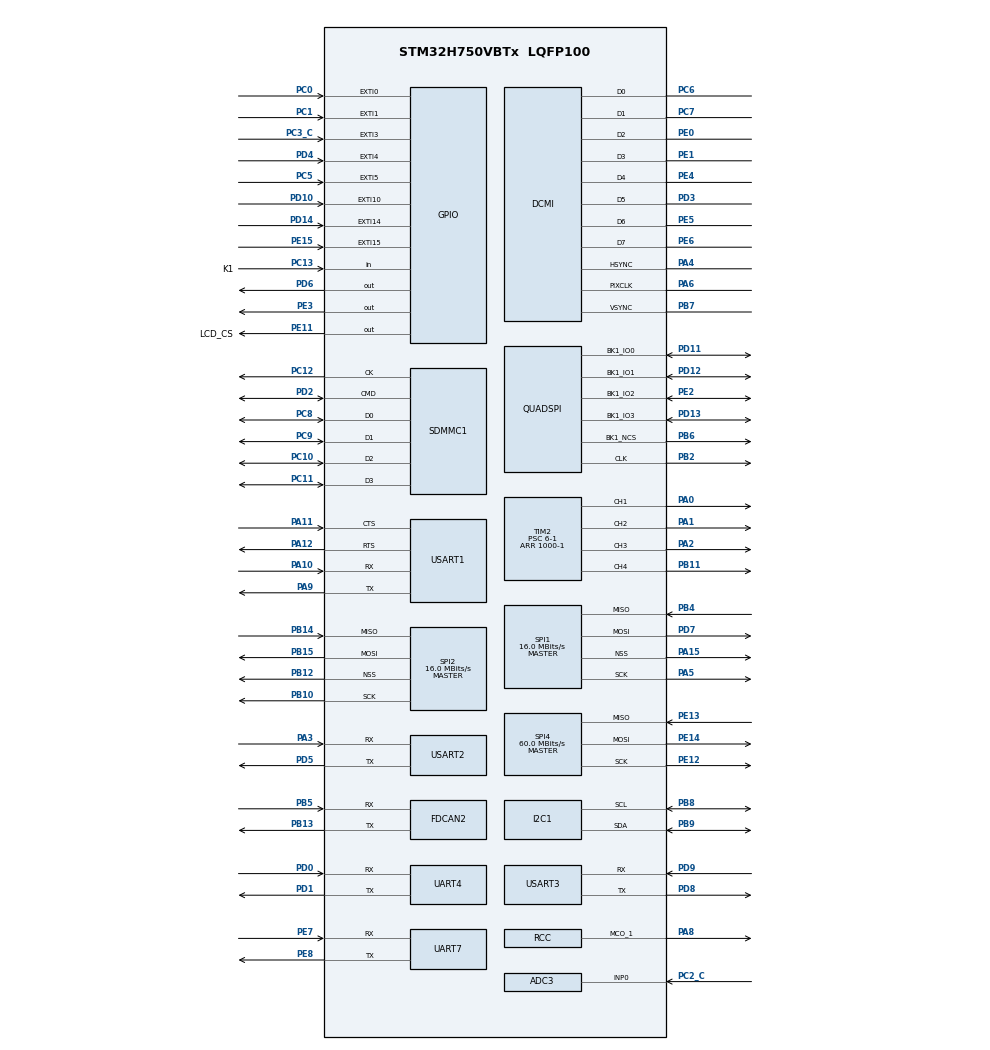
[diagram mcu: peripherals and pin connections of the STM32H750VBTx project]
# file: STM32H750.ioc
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ADC3.Channel-0\#ChannelRegularConversion=ADC_CHANNEL_0
ADC3.Channel-1\#ChannelRegularConversion=ADC_CHANNEL_0
ADC3.Channel-2\#ChannelRegularConversion=ADC_CHANNEL_0
ADC3.Channel-3\#ChannelRegularConversion=ADC_CHANNEL_0
ADC3.DiscontinuousConvMode=ENABLE
ADC3.NbrOfConversion=4
ADC3.NbrOfConversionFlag=1
ADC3.OffsetNumber-0\#ChannelRegularConversion=ADC_OFFSET_NONE
ADC3.OffsetNumber-1\#ChannelRegularConversion=ADC_OFFSET_NONE
ADC3.OffsetNumber-2\#ChannelRegularConversion=ADC_OFFSET_NONE
ADC3.OffsetNumber-3\#ChannelRegularConversion=ADC_OFFSET_NONE
ADC3.OffsetSignedSaturation-0\#ChannelRegularConversion=DISABLE
ADC3.OffsetSignedSaturation-1\#ChannelRegularConversion=DISABLE
ADC3.OffsetSignedSaturation-2\#ChannelRegularConversion=DISABLE
ADC3.OffsetSignedSaturation-3\#ChannelRegularConversion=DISABLE
ADC3.Rank-0\#ChannelRegularConversion=1
ADC3.Rank-1\#ChannelRegularConversion=2
ADC3.Rank-2\#ChannelRegularConversion=3
ADC3.Rank-3\#ChannelRegularConversion=4
ADC3.SamplingTime-0\#ChannelRegularConversion=ADC_SAMPLETIME_1CYCLE_5
ADC3.SamplingTime-1\#ChannelRegularConversion=ADC_SAMPLETIME_1CYCLE_5
ADC3.SamplingTime-2\#ChannelRegularConversion=ADC_SAMPLETIME_1CYCLE_5
ADC3.SamplingTime-3\#ChannelRegularConversion=ADC_SAMPLETIME_1CYCLE_5
CORTEX_M7.default_mode_Activation=1
Dma.DCMI.0.Direction=DMA_PERIPH_TO_MEMORY
Dma.DCMI.0.EventEnable=DISABLE
Dma.DCMI.0.FIFOMode=DMA_FIFOMODE_DISABLE
Dma.DCMI.0.Instance=DMA1_Stream0
Dma.DCMI.0.MemDataAlignment=DMA_MDATAALIGN_WORD
Dma.DCMI.0.MemInc=DMA_MINC_ENABLE
Dma.DCMI.0.Mode=DMA_CIRCULAR
Dma.DCMI.0.PeriphDataAlignment=DMA_PDATAALIGN_WORD
Dma.DCMI.0.PeriphInc=DMA_PINC_DISABLE
Dma.DCMI.0.Polarity=HAL_DMAMUX_REQ_GEN_RISING
Dma.DCMI.0.Priority=DMA_PRIORITY_LOW
Dma.DCMI.0.RequestNumber=1
Dma.DCMI.0.SignalID=NONE
Dma.DCMI.0.SyncEnable=DISABLE
Dma.DCMI.0.SyncPolarity=HAL_DMAMUX_SYNC_NO_EVENT
Dma.DCMI.0.SyncRequestNumber=1
Dma.DCMI.0.SyncSignalID=NONE
Dma.Request0=DCMI
FDCAN2.CalculateBaudRateNominal=1333333
FDCAN2.CalculateTimeBitNominal=750
FDCAN2.CalculateTimeQuantumNominal=250.0
FREERTOS.Tasks01=defaultTask,24,512,StartDefaultTask,Default,NULL,Dynamic,NULL,NULL
FREERTOS.configENABLE_FPU=1
FREERTOS.configMINIMAL_STACK_SIZE=512
FREERTOS.configTOTAL_HEAP_SIZE=131072
I2C1.Timing=0x307075B1
Mcu.Family=STM32H7
Mcu.Name=STM32H750VBTx
Mcu.Package=LQFP100
Mcu.UserConstants=CUSTOM_HID_EPIN_SIZE,0x40U;CUSTOM_HID_EPOUT_SIZE,0x40U
NVIC.DCMI_IRQn=true\:5\:0\:false\:false\:true\:true\:true\:true\:true
NVIC.DMA1_Stream0_IRQn=true\:5\:0\:false\:false\:true\:true\:false\:true\:true
NVIC.PriorityGroup=NVIC_PRIORITYGROUP_4
NVIC.SPI1_IRQn=true\:5\:0\:false\:false\:true\:true\:true\:true\:true
NVIC.TIM16_IRQn=true\:5\:0\:false\:false\:true\:true\:true\:true\:true
PA0.GPIO_Speed=GPIO_SPEED_FREQ_VERY_HIGH
PA0.Signal=S_TIM2_CH1_ETR
PA1.GPIO_Speed=GPIO_SPEED_FREQ_VERY_HIGH
PA1.Signal=S_TIM2_CH2
PA10.Mode=Asynchronous
PA10.Signal=USART1_RX
PA11.Mode=CTS_RTS
PA11.Signal=USART1_CTS
PA12.Mode=CTS_RTS
PA12.Signal=USART1_RTS
PA13\ (JTMS/SWDIO).Mode=Trace_Asynchronous_SW
PA13\ (JTMS/SWDIO).Signal=DEBUG_JTMS-SWDIO
PA14\ (JTCK/SWCLK).Mode=Trace_Asynchronous_SW
PA14\ (JTCK/SWCLK).Signal=DEBUG_JTCK-SWCLK
PA15\ (JTDI).GPIO_Speed=GPIO_SPEED_FREQ_VERY_HIGH
PA15\ (JTDI).Mode=NSS_Signal_Hard_Output
PA15\ (JTDI).Signal=SPI1_NSS
PA2.GPIO_Speed=GPIO_SPEED_FREQ_VERY_HIGH
PA2.Signal=S_TIM2_CH3
PA3.Mode=Asynchronous
PA3.Signal=USART2_RX
PA4.Mode=Slave_8_bits_External_Synchro
PA4.Signal=DCMI_HSYNC
PA5.GPIO_Speed=GPIO_SPEED_FREQ_VERY_HIGH
PA5.Mode=Full_Duplex_Master
PA5.Signal=SPI1_SCK
PA6.Mode=Slave_8_bits_External_Synchro
PA6.Signal=DCMI_PIXCLK
PA8.Mode=Clock-out-1
PA8.Signal=RCC_MCO_1
PA9.Mode=Asynchronous
PA9.Signal=USART1_TX
PB10.Mode=Full_Duplex_Master
PB10.Signal=SPI2_SCK
PB11.GPIO_Speed=GPIO_SPEED_FREQ_VERY_HIGH
PB11.Signal=S_TIM2_CH4
PB12.Mode=NSS_Signal_Hard_Output
PB12.Signal=SPI2_NSS
PB13.GPIO_Speed=GPIO_SPEED_FREQ_VERY_HIGH
PB13.Mode=FDCAN_Activate
PB13.Signal=FDCAN2_TX
PB14.Mode=Full_Duplex_Master
PB14.Signal=SPI2_MISO
PB15.GPIO_Speed=GPIO_SPEED_FREQ_MEDIUM
PB15.Mode=Full_Duplex_Master
PB15.Signal=SPI2_MOSI
PB2.GPIO_Speed=GPIO_SPEED_FREQ_VERY_HIGH
PB2.Mode=Single Bank 1
PB2.Signal=QUADSPI_CLK
PB3\ (JTDO/TRACESWO).Mode=Trace_Asynchronous_SW
PB3\ (JTDO/TRACESWO).Signal=DEBUG_JTDO-SWO
PB4\ (NJTRST).GPIO_Speed=GPIO_SPEED_FREQ_VERY_HIGH
PB4\ (NJTRST).Mode=Full_Duplex_Master
PB4\ (NJTRST).Signal=SPI1_MISO
PB5.Mode=FDCAN_Activate
PB5.Signal=FDCAN2_RX
PB6.GPIO_Speed=GPIO_SPEED_FREQ_VERY_HIGH
PB6.Mode=Single Bank 1
PB6.Signal=QUADSPI_BK1_NCS
PB7.Mode=Slave_8_bits_External_Synchro
PB7.Signal=DCMI_VSYNC
PB8.Mode=I2C
PB8.Signal=I2C1_SCL
PB9.Mode=I2C
PB9.Signal=I2C1_SDA
PC0.Signal=GPXTI0
PC1.Signal=GPXTI1
PC10.Mode=SD_4_bits_Wide_bus
PC10.Signal=SDMMC1_D2
PC11.Mode=SD_4_bits_Wide_bus
PC11.Signal=SDMMC1_D3
PC12.Mode=SD_4_bits_Wide_bus
PC12.Signal=SDMMC1_CK
PC13.GPIO_Label=K1
PC13.GPIO_PuPd=GPIO_PULLDOWN
PC13.Signal=GPIO_Input
PC14-OSC32_IN\ (OSC32_IN).Mode=LSE-External-Oscillator
PC14-OSC32_IN\ (OSC32_IN).Signal=RCC_OSC32_IN
PC15-OSC32_OUT\ (OSC32_OUT).Mode=LSE-External-Oscillator
PC15-OSC32_OUT\ (OSC32_OUT).Signal=RCC_OSC32_OUT
PC2_C.Mode=IN0-Single-Ended
PC2_C.Signal=ADC3_INP0
PC3_C.Signal=GPXTI3
PC5.Signal=GPXTI5
PC6.Mode=Slave_8_bits_External_Synchro
PC6.Signal=DCMI_D0
PC7.Mode=Slave_8_bits_External_Synchro
PC7.Signal=DCMI_D1
PC8.Mode=SD_4_bits_Wide_bus
PC8.Signal=SDMMC1_D0
PC9.Mode=SD_4_bits_Wide_bus
PC9.Signal=SDMMC1_D1
PD0.Mode=Asynchronous
PD0.Signal=UART4_RX
PD1.Mode=Asynchronous
PD1.Signal=UART4_TX
PD10.Signal=GPXTI10
PD11.GPIO_Speed=GPIO_SPEED_FREQ_VERY_HIGH
PD11.Mode=Single Bank 1
PD11.Signal=QUADSPI_BK1_IO0
PD12.GPIO_Speed=GPIO_SPEED_FREQ_VERY_HIGH
PD12.Mode=Single Bank 1
PD12.Signal=QUADSPI_BK1_IO1
PD13.GPIO_Speed=GPIO_SPEED_FREQ_VERY_HIGH
PD13.Mode=Single Bank 1
PD13.Signal=QUADSPI_BK1_IO3
PD14.Signal=GPXTI14
PD2.Mode=SD_4_bits_Wide_bus
PD2.Signal=SDMMC1_CMD
PD3.Mode=Slave_8_bits_External_Synchro
PD3.Signal=DCMI_D5
PD4.Signal=GPXTI4
PD5.Mode=Asynchronous
PD5.Signal=USART2_TX
PD6.GPIO_Speed=GPIO_SPEED_FREQ_HIGH
PD6.Signal=GPIO_Output
PD7.GPIO_Speed=GPIO_SPEED_FREQ_VERY_HIGH
PD7.Mode=Full_Duplex_Master
PD7.Signal=SPI1_MOSI
PD8.Mode=Asynchronous
PD8.Signal=USART3_TX
PD9.Mode=Asynchronous
PD9.Signal=USART3_RX
PE0.Mode=Slave_8_bits_External_Synchro
PE0.Signal=DCMI_D2
PE1.Mode=Slave_8_bits_External_Synchro
PE1.Signal=DCMI_D3
PE11.GPIO_Label=LCD_CS
PE11.GPIO_Speed=GPIO_SPEED_FREQ_VERY_HIGH
PE11.PinState=GPIO_PIN_SET
PE11.Signal=GPIO_Output
PE12.GPIO_Speed=GPIO_SPEED_FREQ_MEDIUM
PE12.Mode=Full_Duplex_Master
PE12.Signal=SPI4_SCK
PE13.Mode=Full_Duplex_Master
PE13.Signal=SPI4_MISO
PE14.GPIO_Speed=GPIO_SPEED_FREQ_MEDIUM
PE14.Mode=Full_Duplex_Master
PE14.Signal=SPI4_MOSI
PE15.Signal=GPXTI15
PE2.GPIO_Speed=GPIO_SPEED_FREQ_VERY_HIGH
PE2.Mode=Single Bank 1
PE2.Signal=QUADSPI_BK1_IO2
PE3.Signal=GPIO_Output
PE4.Mode=Slave_8_bits_External_Synchro
PE4.Signal=DCMI_D4
PE5.Mode=Slave_8_bits_External_Synchro
PE5.Signal=DCMI_D6
PE6.Mode=Slave_8_bits_External_Synchro
PE6.Signal=DCMI_D7
PE7.GPIO_Speed=GPIO_SPEED_FREQ_LOW
PE7.Mode=Asynchronous
PE7.Signal=UART7_RX
PE8.GPIO_Speed=GPIO_SPEED_FREQ_LOW
PE8.Mode=Asynchronous
PE8.Signal=UART7_TX
PH0-OSC_IN\ (PH0).Mode=HSE-External-Oscillator
PH0-OSC_IN\ (PH0).Signal=RCC_OSC_IN
PH1-OSC_OUT\ (PH1).Mode=HSE-External-Oscillator
PH1-OSC_OUT\ (PH1).Signal=RCC_OSC_OUT
ProjectManager.HeapSize=0x200
ProjectManager.StackSize=0x400
ProjectManager.TargetToolchain=Makefile
RCC.ADCFreq_Value=75000000
RCC.APB1Freq_Value=120000000
RCC.APB2Freq_Value=120000000
RCC.APB3Freq_Value=120000000
RCC.APB4Freq_Value=120000000
RCC.CSICalibrationValue=16
RCC.CortexFreq_Value=480000000
RCC.D1PPRE=RCC_APB3_DIV2
RCC.D2PPRE1=RCC_APB1_DIV2
RCC.D2PPRE2=RCC_APB2_DIV2
RCC.D3PPRE=RCC_APB4_DIV2
RCC.DIVM1=5
RCC.DIVM2=2
RCC.DIVN1=192
RCC.DIVN2=12
RCC.DIVQ1=15
RCC.DIVR2=1
RCC.HCLKFreq_Value=240000000
RCC.HPRE=RCC_HCLK_DIV2
RCC.HSICalibrationValue=32
RCC.PLL1_VCO_SEL=RCC_PLL1VCOWIDE
RCC.PLL2FRACN=0
RCC.PLL3FRACN=0
RCC.PLLFRACN=0
RCC.PLLSourceVirtual=RCC_PLLSOURCE_HSE
RCC.PWR_Regulator_Voltage_Scale=PWR_REGULATOR_VOLTAGE_SCALE0
RCC.ProductRev=revV
RCC.RCC_TIM_PRescaler_Selection=RCC_TIMPRES_DESACTIVATED
RCC.SYSCLKFreq_VALUE=480000000
RCC.SYSCLKSource=RCC_SYSCLKSOURCE_PLLCLK
RCC.SupplySource=PWR_LDO_SUPPLY
RCC.USBFreq_Value=64000000
SDMMC1.ClockDiv=5
SH.S_TIM2_CH1_ETR.0=TIM2_CH1,PWM Generation1 CH1
SH.S_TIM2_CH2.0=TIM2_CH2,PWM Generation2 CH2
SH.S_TIM2_CH3.0=TIM2_CH3,PWM Generation3 CH3
SH.S_TIM2_CH4.0=TIM2_CH4,PWM Generation4 CH4
SPI1.BaudRatePrescaler=SPI_BAUDRATEPRESCALER_4
SPI1.CRCCalculation=SPI_CRCCALCULATION_DISABLE
SPI1.CalculateBaudRate=16.0 MBits/s
SPI1.DataSize=SPI_DATASIZE_8BIT
SPI1.Direction=SPI_DIRECTION_2LINES
SPI1.Mode=SPI_MODE_MASTER
SPI1.VirtualNSS=VM_NSSHARD
SPI1.VirtualType=VM_MASTER
SPI2.BaudRatePrescaler=SPI_BAUDRATEPRESCALER_4
SPI2.CalculateBaudRate=16.0 MBits/s
SPI2.DataSize=SPI_DATASIZE_8BIT
SPI2.Direction=SPI_DIRECTION_2LINES
SPI2.Mode=SPI_MODE_MASTER
SPI2.NSSPolarity=SPI_NSS_POLARITY_LOW
SPI2.VirtualNSS=VM_NSSHARD
SPI2.VirtualType=VM_MASTER
SPI4.CalculateBaudRate=60.0 MBits/s
SPI4.Direction=SPI_DIRECTION_2LINES
SPI4.Mode=SPI_MODE_MASTER
SPI4.VirtualType=VM_MASTER
TIM16.Period=100-1
TIM16.Prescaler=120-1
TIM2.AutoReloadPreload=TIM_AUTORELOAD_PRELOAD_ENABLE
TIM2.Channel-PWM\ Generation1\ CH1=TIM_CHANNEL_1
TIM2.Channel-PWM\ Generation2\ CH2=TIM_CHANNEL_2
TIM2.Channel-PWM\ Generation3\ CH3=TIM_CHANNEL_3
TIM2.Channel-PWM\ Generation4\ CH4=TIM_CHANNEL_4
TIM2.OCFastMode_PWM-PWM\ Generation1\ CH1=TIM_OCFAST_DISABLE
TIM2.OCFastMode_PWM-PWM\ Generation2\ CH2=TIM_OCFAST_DISABLE
TIM2.OCFastMode_PWM-PWM\ Generation3\ CH3=TIM_OCFAST_DISABLE
TIM2.OCFastMode_PWM-PWM\ Generation4\ CH4=TIM_OCFAST_DISABLE
TIM2.Period=1000-1
TIM2.Prescaler=6-1
USART1.VirtualMode-Asynchronous=VM_ASYNC
USART2.VirtualMode-Asynchronous=VM_ASYNC
USART3.VirtualMode-Asynchronous=VM_ASYNC
VP_ADC3_TempSens_Input.Mode=IN-TempSens
VP_ADC3_Vbat_Input.Mode=IN-Vbat
VP_ADC3_Vref_Input.Mode=IN-Vrefint
VP_FREERTOS_VS_CMSIS_V2.Mode=CMSIS_V2
VP_MEMORYMAP_VS_MEMORYMAP.Mode=CurAppReg
VP_RNG_VS_RNG.Mode=RNG_Activate
VP_RTC_VS_RTC_Activate.Mode=RTC_Enabled
VP_RTC_VS_RTC_Calendar.Mode=RTC_Calendar
VP_TIM16_VS_ClockSourceINT.Mode=Enable_Timer
VP_VREFBUF_V_VREFBUF.Mode=ExternalMode
board=custom

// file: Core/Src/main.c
/* USER CODE BEGIN Header */
/**
  ******************************************************************************
  * @file           : main.c
  * @brief          : Main program body
  ******************************************************************************
  * @attention
  *
  * Copyright (c) 2026 STMicroelectronics.
  * All rights reserved.
  *
  * This software is licensed under terms that can be found in the LICENSE file
  * in the root directory of this software component.
  * If no LICENSE file comes with this software, it is provided AS-IS.
  *
  ******************************************************************************
  */
/* USER CODE END Header */
#include "main.h"
#include "FreeRTOS.h"
#include "cmsis_os2.h"

/* USER CODE BEGIN Includes */
#include "debug_uart.h"
/* USER CODE END Includes */

ADC_HandleTypeDef hadc3;

DCMI_HandleTypeDef hdcmi;
DMA_HandleTypeDef hdma_dcmi;

FDCAN_HandleTypeDef hfdcan2;

I2C_HandleTypeDef hi2c1;

QSPI_HandleTypeDef hqspi;

RNG_HandleTypeDef hrng;

RTC_HandleTypeDef hrtc;

SD_HandleTypeDef hsd1;

SPI_HandleTypeDef hspi1;
SPI_HandleTypeDef hspi2;
SPI_HandleTypeDef hspi4;

TIM_HandleTypeDef htim2;
TIM_HandleTypeDef htim16;

UART_HandleTypeDef huart4;
UART_HandleTypeDef huart7;
UART_HandleTypeDef huart1;
UART_HandleTypeDef huart2;
UART_HandleTypeDef huart3;

/* Definitions for defaultTask */
osThreadId_t defaultTaskHandle;
const osThreadAttr_t defaultTask_attributes = {
  .name = "defaultTask",
  .stack_size = 512 * 4,
  .priority = (osPriority_t) osPriorityNormal,
};

void SystemClock_Config(void);
static void MPU_Config(void);
static void MX_GPIO_Init(void);
static void MX_DMA_Init(void);
static void MX_DCMI_Init(void);
static void MX_I2C1_Init(void);
static void MX_QUADSPI_Init(void);
static void MX_RNG_Init(void);
static void MX_RTC_Init(void);
static void MX_SDMMC1_SD_Init(void);
static void MX_SPI4_Init(void);
static void MX_ADC3_Init(void);
static void MX_SPI1_Init(void);
static void MX_TIM16_Init(void);
static void MX_FDCAN2_Init(void);
static void MX_UART7_Init(void);
static void MX_UART4_Init(void);
static void MX_SPI2_Init(void);
static void MX_USART1_UART_Init(void);
static void MX_USART2_UART_Init(void);
static void MX_TIM2_Init(void);
static void MX_USART3_UART_Init(void);
void StartDefaultTask(void *argument);
void MX_FREERTOS_Init(void);

int main(void)
{

  /* MPU Configuration--------------------------------------------------------*/
  MPU_Config();

  /* MCU Configuration--------------------------------------------------------*/

  /* Reset of all peripherals, Initializes the Flash interface and the Systick. */
  HAL_Init();

  /* Configure the system clock */
  SystemClock_Config();

  /* Initialize all configured peripherals */
  MX_GPIO_Init();
  MX_DMA_Init();
  MX_DCMI_Init();
  MX_I2C1_Init();
  MX_QUADSPI_Init();
  MX_RNG_Init();
  MX_RTC_Init();
  MX_SDMMC1_SD_Init();
  MX_SPI4_Init();
  MX_ADC3_Init();
  MX_SPI1_Init();
  MX_TIM16_Init();
  MX_FDCAN2_Init();
  MX_UART7_Init();
  MX_UART4_Init();
  MX_SPI2_Init();
  MX_USART1_UART_Init();
  MX_USART2_UART_Init();
  MX_TIM2_Init();
  MX_USART3_UART_Init();
  /* USER CODE BEGIN 2 */

   /* Initialize Debug UART for PC communication */
   Debug_UART_Init();
   Debug_Test();

  /* USER CODE END 2 */

  /* Init scheduler */
  osKernelInitialize();

  /* Create the thread(s) */
  /* creation of defaultTask - moved to MX_FREERTOS_Init() in freertos.c */

  /* Initialize all RTOS resources and create application tasks */
  MX_FREERTOS_Init();

  /* Start scheduler */
  osKernelStart();

  /* We should never get here as control is now taken by the scheduler */

  /* Infinite loop */
  while (1)
  {

  }
}

void SystemClock_Config(void)
{
  RCC_OscInitTypeDef RCC_OscInitStruct = {0};
  RCC_ClkInitTypeDef RCC_ClkInitStruct = {0};

  /** Supply configuration update enable
  */
  HAL_PWREx_ConfigSupply(PWR_LDO_SUPPLY);

  /** Configure the main internal regulator output voltage
  */
  __HAL_PWR_VOLTAGESCALING_CONFIG(PWR_REGULATOR_VOLTAGE_SCALE0);

  while(!__HAL_PWR_GET_FLAG(PWR_FLAG_VOSRDY)) {}

  /** Initializes the RCC Oscillators according to the specified parameters
  * in the RCC_OscInitTypeDef structure.
  */
  RCC_OscInitStruct.OscillatorType = RCC_OSCILLATORTYPE_HSI48|RCC_OSCILLATORTYPE_HSI
                              |RCC_OSCILLATORTYPE_LSI|RCC_OSCILLATORTYPE_HSE;
  RCC_OscInitStruct.HSEState = RCC_HSE_ON;
  RCC_OscInitStruct.HSIState = RCC_HSI_DIV1;
  RCC_OscInitStruct.HSICalibrationValue = 32;
  RCC_OscInitStruct.LSIState = RCC_LSI_ON;
  RCC_OscInitStruct.HSI48State = RCC_HSI48_ON;
  RCC_OscInitStruct.PLL.PLLState = RCC_PLL_ON;
  RCC_OscInitStruct.PLL.PLLSource = RCC_PLLSOURCE_HSE;
  RCC_OscInitStruct.PLL.PLLM = 5;
  RCC_OscInitStruct.PLL.PLLN = 192;
  RCC_OscInitStruct.PLL.PLLP = 2;
  RCC_OscInitStruct.PLL.PLLQ = 15;
  RCC_OscInitStruct.PLL.PLLR = 2;
  RCC_OscInitStruct.PLL.PLLRGE = RCC_PLL1VCIRANGE_2;
  RCC_OscInitStruct.PLL.PLLVCOSEL = RCC_PLL1VCOWIDE;
  RCC_OscInitStruct.PLL.PLLFRACN = 0;
  if (HAL_RCC_OscConfig(&RCC_OscInitStruct) != HAL_OK)
  {
    Error_Handler();
  }

  /** Initializes the CPU, AHB and APB buses clocks
  */
  RCC_ClkInitStruct.ClockType = RCC_CLOCKTYPE_HCLK|RCC_CLOCKTYPE_SYSCLK
                              |RCC_CLOCKTYPE_PCLK1|RCC_CLOCKTYPE_PCLK2
                              |RCC_CLOCKTYPE_D3PCLK1|RCC_CLOCKTYPE_D1PCLK1;
  RCC_ClkInitStruct.SYSCLKSource = RCC_SYSCLKSOURCE_PLLCLK;
  RCC_ClkInitStruct.SYSCLKDivider = RCC_SYSCLK_DIV1;
  RCC_ClkInitStruct.AHBCLKDivider = RCC_HCLK_DIV2;
  RCC_ClkInitStruct.APB3CLKDivider = RCC_APB3_DIV2;
  RCC_ClkInitStruct.APB1CLKDivider = RCC_APB1_DIV2;
  RCC_ClkInitStruct.APB2CLKDivider = RCC_APB2_DIV2;
  RCC_ClkInitStruct.APB4CLKDivider = RCC_APB4_DIV2;

  if (HAL_RCC_ClockConfig(&RCC_ClkInitStruct, FLASH_LATENCY_4) != HAL_OK)
  {
    Error_Handler();
  }
  HAL_RCC_MCOConfig(RCC_MCO1, RCC_MCO1SOURCE_HSI, RCC_MCODIV_1);
}

static void MX_ADC3_Init(void)
{

  ADC_ChannelConfTypeDef sConfig = {0};

  /** Common config
  */
  hadc3.Instance = ADC3;
  hadc3.Init.Resolution = ADC_RESOLUTION_16B;
  hadc3.Init.ScanConvMode = ADC_SCAN_ENABLE;
  hadc3.Init.EOCSelection = ADC_EOC_SINGLE_CONV;
  hadc3.Init.LowPowerAutoWait = DISABLE;
  hadc3.Init.ContinuousConvMode = DISABLE;
  hadc3.Init.NbrOfConversion = 4;
  hadc3.Init.DiscontinuousConvMode = ENABLE;
  hadc3.Init.NbrOfDiscConversion = 1;
  hadc3.Init.ExternalTrigConv = ADC_SOFTWARE_START;
  hadc3.Init.ExternalTrigConvEdge = ADC_EXTERNALTRIGCONVEDGE_NONE;
  hadc3.Init.ConversionDataManagement = ADC_CONVERSIONDATA_DR;
  hadc3.Init.Overrun = ADC_OVR_DATA_PRESERVED;
  hadc3.Init.LeftBitShift = ADC_LEFTBITSHIFT_NONE;
  hadc3.Init.OversamplingMode = DISABLE;
  hadc3.Init.Oversampling.Ratio = 1;
  if (HAL_ADC_Init(&hadc3) != HAL_OK)
  {
    Error_Handler();
  }

  /** Configure Regular Channel
  */
  sConfig.Channel = ADC_CHANNEL_0;
  sConfig.Rank = ADC_REGULAR_RANK_1;
  sConfig.SamplingTime = ADC_SAMPLETIME_1CYCLE_5;
  sConfig.SingleDiff = ADC_SINGLE_ENDED;
  sConfig.OffsetNumber = ADC_OFFSET_NONE;
  sConfig.Offset = 0;
  sConfig.OffsetSignedSaturation = DISABLE;
  if (HAL_ADC_ConfigChannel(&hadc3, &sConfig) != HAL_OK)
  {
    Error_Handler();
  }

  /** Configure Regular Channel
  */
  sConfig.Rank = ADC_REGULAR_RANK_2;
  if (HAL_ADC_ConfigChannel(&hadc3, &sConfig) != HAL_OK)
  {
    Error_Handler();
  }

  /** Configure Regular Channel
  */
  sConfig.Rank = ADC_REGULAR_RANK_3;
  if (HAL_ADC_ConfigChannel(&hadc3, &sConfig) != HAL_OK)
  {
    Error_Handler();
  }

  /** Configure Regular Channel
  */
  sConfig.Rank = ADC_REGULAR_RANK_4;
  if (HAL_ADC_ConfigChannel(&hadc3, &sConfig) != HAL_OK)
  {
    Error_Handler();
  }

}

static void MX_DCMI_Init(void)
{

  hdcmi.Instance = DCMI;
  hdcmi.Init.SynchroMode = DCMI_SYNCHRO_HARDWARE;
  hdcmi.Init.PCKPolarity = DCMI_PCKPOLARITY_FALLING;
  hdcmi.Init.VSPolarity = DCMI_VSPOLARITY_LOW;
  hdcmi.Init.HSPolarity = DCMI_HSPOLARITY_LOW;
  hdcmi.Init.CaptureRate = DCMI_CR_ALL_FRAME;
  hdcmi.Init.ExtendedDataMode = DCMI_EXTEND_DATA_8B;
  hdcmi.Init.JPEGMode = DCMI_JPEG_DISABLE;
  hdcmi.Init.ByteSelectMode = DCMI_BSM_ALL;
  hdcmi.Init.ByteSelectStart = DCMI_OEBS_ODD;
  hdcmi.Init.LineSelectMode = DCMI_LSM_ALL;
  hdcmi.Init.LineSelectStart = DCMI_OELS_ODD;
  if (HAL_DCMI_Init(&hdcmi) != HAL_OK)
  {
    Error_Handler();
  }

}

static void MX_FDCAN2_Init(void)
{

  hfdcan2.Instance = FDCAN2;
  hfdcan2.Init.FrameFormat = FDCAN_FRAME_CLASSIC;
  hfdcan2.Init.Mode = FDCAN_MODE_NORMAL;
  hfdcan2.Init.AutoRetransmission = DISABLE;
  hfdcan2.Init.TransmitPause = DISABLE;
  hfdcan2.Init.ProtocolException = DISABLE;
  hfdcan2.Init.NominalPrescaler = 16;
  hfdcan2.Init.NominalSyncJumpWidth = 1;
  hfdcan2.Init.NominalTimeSeg1 = 1;
  hfdcan2.Init.NominalTimeSeg2 = 1;
  hfdcan2.Init.DataPrescaler = 1;
  hfdcan2.Init.DataSyncJumpWidth = 1;
  hfdcan2.Init.DataTimeSeg1 = 1;
  hfdcan2.Init.DataTimeSeg2 = 1;
  hfdcan2.Init.MessageRAMOffset = 0;
  hfdcan2.Init.StdFiltersNbr = 0;
  hfdcan2.Init.ExtFiltersNbr = 0;
  hfdcan2.Init.RxFifo0ElmtsNbr = 0;
  hfdcan2.Init.RxFifo0ElmtSize = FDCAN_DATA_BYTES_8;
  hfdcan2.Init.RxFifo1ElmtsNbr = 0;
  hfdcan2.Init.RxFifo1ElmtSize = FDCAN_DATA_BYTES_8;
  hfdcan2.Init.RxBuffersNbr = 0;
  hfdcan2.Init.RxBufferSize = FDCAN_DATA_BYTES_8;
  hfdcan2.Init.TxEventsNbr = 0;
  hfdcan2.Init.TxBuffersNbr = 0;
  hfdcan2.Init.TxFifoQueueElmtsNbr = 0;
  hfdcan2.Init.TxFifoQueueMode = FDCAN_TX_FIFO_OPERATION;
  hfdcan2.Init.TxElmtSize = FDCAN_DATA_BYTES_8;
  if (HAL_FDCAN_Init(&hfdcan2) != HAL_OK)
  {
    Error_Handler();
  }
  /* USER CODE BEGIN FDCAN2_Init 2 */
  /* Reconfigure FDCAN2 for RX FIFO */
  hfdcan2.Init.StdFiltersNbr = 1;
  hfdcan2.Init.RxFifo0ElmtsNbr = 8;
  hfdcan2.Init.RxFifo0ElmtSize = FDCAN_DATA_BYTES_8;
  hfdcan2.Init.RxBuffersNbr = 0;
  hfdcan2.Init.TxBuffersNbr = 3;
  hfdcan2.Init.TxFifoQueueElmtsNbr = 4;
  HAL_FDCAN_Init(&hfdcan2);
  /* USER CODE END FDCAN2_Init 2 */

}

static void MX_I2C1_Init(void)
{

  hi2c1.Instance = I2C1;
  hi2c1.Init.Timing = 0x307075B1;
  hi2c1.Init.OwnAddress1 = 0;
  hi2c1.Init.AddressingMode = I2C_ADDRESSINGMODE_7BIT;
  hi2c1.Init.DualAddressMode = I2C_DUALADDRESS_DISABLE;
  hi2c1.Init.OwnAddress2 = 0;
  hi2c1.Init.OwnAddress2Masks = I2C_OA2_NOMASK;
  hi2c1.Init.GeneralCallMode = I2C_GENERALCALL_DISABLE;
  hi2c1.Init.NoStretchMode = I2C_NOSTRETCH_DISABLE;
  if (HAL_I2C_Init(&hi2c1) != HAL_OK)
  {
    Error_Handler();
  }

  /** Configure Analogue filter
  */
  if (HAL_I2CEx_ConfigAnalogFilter(&hi2c1, I2C_ANALOGFILTER_ENABLE) != HAL_OK)
  {
    Error_Handler();
  }

  /** Configure Digital filter
  */
  if (HAL_I2CEx_ConfigDigitalFilter(&hi2c1, 0) != HAL_OK)
  {
    Error_Handler();
  }

}

static void MX_QUADSPI_Init(void)
{

  /* QUADSPI parameter configuration*/
  hqspi.Instance = QUADSPI;
  hqspi.Init.ClockPrescaler = 255;
  hqspi.Init.FifoThreshold = 1;
  hqspi.Init.SampleShifting = QSPI_SAMPLE_SHIFTING_NONE;
  hqspi.Init.FlashSize = 1;
  hqspi.Init.ChipSelectHighTime = QSPI_CS_HIGH_TIME_1_CYCLE;
  hqspi.Init.ClockMode = QSPI_CLOCK_MODE_0;
  hqspi.Init.FlashID = QSPI_FLASH_ID_1;
  hqspi.Init.DualFlash = QSPI_DUALFLASH_DISABLE;
  if (HAL_QSPI_Init(&hqspi) != HAL_OK)
  {
    Error_Handler();
  }

}

static void MX_RNG_Init(void)
{

  hrng.Instance = RNG;
  hrng.Init.ClockErrorDetection = RNG_CED_ENABLE;
  if (HAL_RNG_Init(&hrng) != HAL_OK)
  {
    Error_Handler();
  }

}

static void MX_RTC_Init(void)
{

  RTC_TimeTypeDef sTime = {0};
  RTC_DateTypeDef sDate = {0};

  /** Initialize RTC Only
  */
  hrtc.Instance = RTC;
  hrtc.Init.HourFormat = RTC_HOURFORMAT_24;
  hrtc.Init.AsynchPrediv = 127;
  hrtc.Init.SynchPrediv = 255;
  hrtc.Init.OutPut = RTC_OUTPUT_DISABLE;
  hrtc.Init.OutPutPolarity = RTC_OUTPUT_POLARITY_HIGH;
  hrtc.Init.OutPutType = RTC_OUTPUT_TYPE_OPENDRAIN;
  hrtc.Init.OutPutRemap = RTC_OUTPUT_REMAP_NONE;
  if (HAL_RTC_Init(&hrtc) != HAL_OK)
  {
    Error_Handler();
  }

  /** Initialize RTC and set the Time and Date
  */
  sTime.Hours = 0x0;
  sTime.Minutes = 0x0;
  sTime.Seconds = 0x0;
  sTime.DayLightSaving = RTC_DAYLIGHTSAVING_NONE;
  sTime.StoreOperation = RTC_STOREOPERATION_RESET;
  if (HAL_RTC_SetTime(&hrtc, &sTime, RTC_FORMAT_BCD) != HAL_OK)
  {
    Error_Handler();
  }
  sDate.WeekDay = RTC_WEEKDAY_MONDAY;
  sDate.Month = RTC_MONTH_JANUARY;
  sDate.Date = 0x1;
  sDate.Year = 0x0;

  if (HAL_RTC_SetDate(&hrtc, &sDate, RTC_FORMAT_BCD) != HAL_OK)
  {
    Error_Handler();
  }

}

static void MX_SDMMC1_SD_Init(void)
{

  hsd1.Instance = SDMMC1;
  hsd1.Init.ClockEdge = SDMMC_CLOCK_EDGE_RISING;
  hsd1.Init.ClockPowerSave = SDMMC_CLOCK_POWER_SAVE_DISABLE;
  hsd1.Init.BusWide = SDMMC_BUS_WIDE_4B;
  hsd1.Init.HardwareFlowControl = SDMMC_HARDWARE_FLOW_CONTROL_DISABLE;
  hsd1.Init.ClockDiv = 5;
  if (HAL_SD_Init(&hsd1) != HAL_OK)
  {
    Error_Handler();
  }

}

static void MX_SPI1_Init(void)
{

  /* SPI1 parameter configuration*/
  hspi1.Instance = SPI1;
  hspi1.Init.Mode = SPI_MODE_MASTER;
  hspi1.Init.Direction = SPI_DIRECTION_2LINES;
  hspi1.Init.DataSize = SPI_DATASIZE_8BIT;
  hspi1.Init.CLKPolarity = SPI_POLARITY_LOW;
  hspi1.Init.CLKPhase = SPI_PHASE_1EDGE;
  hspi1.Init.NSS = SPI_NSS_HARD_OUTPUT;
  hspi1.Init.BaudRatePrescaler = SPI_BAUDRATEPRESCALER_4;
  hspi1.Init.FirstBit = SPI_FIRSTBIT_MSB;
  hspi1.Init.TIMode = SPI_TIMODE_DISABLE;
  hspi1.Init.CRCCalculation = SPI_CRCCALCULATION_DISABLE;
  hspi1.Init.CRCPolynomial = 0x0;
  hspi1.Init.NSSPMode = SPI_NSS_PULSE_ENABLE;
  hspi1.Init.NSSPolarity = SPI_NSS_POLARITY_LOW;
  hspi1.Init.FifoThreshold = SPI_FIFO_THRESHOLD_01DATA;
  hspi1.Init.TxCRCInitializationPattern = SPI_CRC_INITIALIZATION_ALL_ZERO_PATTERN;
  hspi1.Init.RxCRCInitializationPattern = SPI_CRC_INITIALIZATION_ALL_ZERO_PATTERN;
  hspi1.Init.MasterSSIdleness = SPI_MASTER_SS_IDLENESS_00CYCLE;
  hspi1.Init.MasterInterDataIdleness = SPI_MASTER_INTERDATA_IDLENESS_00CYCLE;
  hspi1.Init.MasterReceiverAutoSusp = SPI_MASTER_RX_AUTOSUSP_DISABLE;
  hspi1.Init.MasterKeepIOState = SPI_MASTER_KEEP_IO_STATE_DISABLE;
  hspi1.Init.IOSwap = SPI_IO_SWAP_DISABLE;
  if (HAL_SPI_Init(&hspi1) != HAL_OK)
  {
    Error_Handler();
  }

}

static void MX_SPI2_Init(void)
{

  /* SPI2 parameter configuration*/
  hspi2.Instance = SPI2;
  hspi2.Init.Mode = SPI_MODE_MASTER;
  hspi2.Init.Direction = SPI_DIRECTION_2LINES;
  hspi2.Init.DataSize = SPI_DATASIZE_8BIT;
  hspi2.Init.CLKPolarity = SPI_POLARITY_LOW;
  hspi2.Init.CLKPhase = SPI_PHASE_1EDGE;
  hspi2.Init.NSS = SPI_NSS_HARD_OUTPUT;
  hspi2.Init.BaudRatePrescaler = SPI_BAUDRATEPRESCALER_2;
  hspi2.Init.FirstBit = SPI_FIRSTBIT_MSB;
  hspi2.Init.TIMode = SPI_TIMODE_DISABLE;
  hspi2.Init.CRCCalculation = SPI_CRCCALCULATION_DISABLE;
  hspi2.Init.CRCPolynomial = 0x0;
  hspi2.Init.NSSPMode = SPI_NSS_PULSE_ENABLE;
  hspi2.Init.NSSPolarity = SPI_NSS_POLARITY_LOW;
  hspi2.Init.FifoThreshold = SPI_FIFO_THRESHOLD_01DATA;
  hspi2.Init.TxCRCInitializationPattern = SPI_CRC_INITIALIZATION_ALL_ZERO_PATTERN;
  hspi2.Init.RxCRCInitializationPattern = SPI_CRC_INITIALIZATION_ALL_ZERO_PATTERN;
  hspi2.Init.MasterSSIdleness = SPI_MASTER_SS_IDLENESS_00CYCLE;
  hspi2.Init.MasterInterDataIdleness = SPI_MASTER_INTERDATA_IDLENESS_00CYCLE;
  hspi2.Init.MasterReceiverAutoSusp = SPI_MASTER_RX_AUTOSUSP_DISABLE;
  hspi2.Init.MasterKeepIOState = SPI_MASTER_KEEP_IO_STATE_DISABLE;
  hspi2.Init.IOSwap = SPI_IO_SWAP_DISABLE;
  if (HAL_SPI_Init(&hspi2) != HAL_OK)
  {
    Error_Handler();
  }

}

static void MX_SPI4_Init(void)
{

  /* SPI4 parameter configuration*/
  hspi4.Instance = SPI4;
  hspi4.Init.Mode = SPI_MODE_MASTER;
  hspi4.Init.Direction = SPI_DIRECTION_2LINES;
  hspi4.Init.DataSize = SPI_DATASIZE_4BIT;
  hspi4.Init.CLKPolarity = SPI_POLARITY_LOW;
  hspi4.Init.CLKPhase = SPI_PHASE_1EDGE;
  hspi4.Init.NSS = SPI_NSS_SOFT;
  hspi4.Init.BaudRatePrescaler = SPI_BAUDRATEPRESCALER_2;
  hspi4.Init.FirstBit = SPI_FIRSTBIT_MSB;
  hspi4.Init.TIMode = SPI_TIMODE_DISABLE;
  hspi4.Init.CRCCalculation = SPI_CRCCALCULATION_DISABLE;
  hspi4.Init.CRCPolynomial = 0x0;
  hspi4.Init.NSSPMode = SPI_NSS_PULSE_ENABLE;
  hspi4.Init.NSSPolarity = SPI_NSS_POLARITY_LOW;
  hspi4.Init.FifoThreshold = SPI_FIFO_THRESHOLD_01DATA;
  hspi4.Init.TxCRCInitializationPattern = SPI_CRC_INITIALIZATION_ALL_ZERO_PATTERN;
  hspi4.Init.RxCRCInitializationPattern = SPI_CRC_INITIALIZATION_ALL_ZERO_PATTERN;
  hspi4.Init.MasterSSIdleness = SPI_MASTER_SS_IDLENESS_00CYCLE;
  hspi4.Init.MasterInterDataIdleness = SPI_MASTER_INTERDATA_IDLENESS_00CYCLE;
  hspi4.Init.MasterReceiverAutoSusp = SPI_MASTER_RX_AUTOSUSP_DISABLE;
  hspi4.Init.MasterKeepIOState = SPI_MASTER_KEEP_IO_STATE_DISABLE;
  hspi4.Init.IOSwap = SPI_IO_SWAP_DISABLE;
  if (HAL_SPI_Init(&hspi4) != HAL_OK)
  {
    Error_Handler();
  }

}

static void MX_TIM2_Init(void)
{

  TIM_MasterConfigTypeDef sMasterConfig = {0};
  TIM_OC_InitTypeDef sConfigOC = {0};

  htim2.Instance = TIM2;
  htim2.Init.Prescaler = 6-1;
  htim2.Init.CounterMode = TIM_COUNTERMODE_UP;
  htim2.Init.Period = 1000-1;
  htim2.Init.ClockDivision = TIM_CLOCKDIVISION_DIV1;
  htim2.Init.AutoReloadPreload = TIM_AUTORELOAD_PRELOAD_ENABLE;
  if (HAL_TIM_PWM_Init(&htim2) != HAL_OK)
  {
    Error_Handler();
  }
  sMasterConfig.MasterOutputTrigger = TIM_TRGO_RESET;
  sMasterConfig.MasterSlaveMode = TIM_MASTERSLAVEMODE_DISABLE;
  if (HAL_TIMEx_MasterConfigSynchronization(&htim2, &sMasterConfig) != HAL_OK)
  {
    Error_Handler();
  }
  sConfigOC.OCMode = TIM_OCMODE_PWM1;
  sConfigOC.Pulse = 0;
  sConfigOC.OCPolarity = TIM_OCPOLARITY_HIGH;
  sConfigOC.OCFastMode = TIM_OCFAST_DISABLE;
  if (HAL_TIM_PWM_ConfigChannel(&htim2, &sConfigOC, TIM_CHANNEL_1) != HAL_OK)
  {
    Error_Handler();
  }
  if (HAL_TIM_PWM_ConfigChannel(&htim2, &sConfigOC, TIM_CHANNEL_2) != HAL_OK)
  {
    Error_Handler();
  }
  if (HAL_TIM_PWM_ConfigChannel(&htim2, &sConfigOC, TIM_CHANNEL_3) != HAL_OK)
  {
    Error_Handler();
  }
  if (HAL_TIM_PWM_ConfigChannel(&htim2, &sConfigOC, TIM_CHANNEL_4) != HAL_OK)
  {
    Error_Handler();
  }
  HAL_TIM_MspPostInit(&htim2);

}

static void MX_TIM16_Init(void)
{

  htim16.Instance = TIM16;
  htim16.Init.Prescaler = 120-1;
  htim16.Init.CounterMode = TIM_COUNTERMODE_UP;
  htim16.Init.Period = 100-1;
  htim16.Init.ClockDivision = TIM_CLOCKDIVISION_DIV1;
  htim16.Init.RepetitionCounter = 0;
  htim16.Init.AutoReloadPreload = TIM_AUTORELOAD_PRELOAD_DISABLE;
  if (HAL_TIM_Base_Init(&htim16) != HAL_OK)
  {
    Error_Handler();
  }

}

static void MX_UART4_Init(void)
{

  huart4.Instance = UART4;
  huart4.Init.BaudRate = 115200;
  huart4.Init.WordLength = UART_WORDLENGTH_8B;
  huart4.Init.StopBits = UART_STOPBITS_1;
  huart4.Init.Parity = UART_PARITY_NONE;
  huart4.Init.Mode = UART_MODE_TX_RX;
  huart4.Init.HwFlowCtl = UART_HWCONTROL_NONE;
  huart4.Init.OverSampling = UART_OVERSAMPLING_16;
  huart4.Init.OneBitSampling = UART_ONE_BIT_SAMPLE_DISABLE;
  huart4.Init.ClockPrescaler = UART_PRESCALER_DIV1;
  huart4.AdvancedInit.AdvFeatureInit = UART_ADVFEATURE_NO_INIT;
  if (HAL_UART_Init(&huart4) != HAL_OK)
  {
    Error_Handler();
  }
  if (HAL_UARTEx_SetTxFifoThreshold(&huart4, UART_TXFIFO_THRESHOLD_1_8) != HAL_OK)
  {
    Error_Handler();
  }
  if (HAL_UARTEx_SetRxFifoThreshold(&huart4, UART_RXFIFO_THRESHOLD_1_8) != HAL_OK)
  {
    Error_Handler();
  }
  if (HAL_UARTEx_DisableFifoMode(&huart4) != HAL_OK)
  {
    Error_Handler();
  }

}

static void MX_UART7_Init(void)
{

  huart7.Instance = UART7;
  huart7.Init.BaudRate = 115200;
  huart7.Init.WordLength = UART_WORDLENGTH_8B;
  huart7.Init.StopBits = UART_STOPBITS_1;
  huart7.Init.Parity = UART_PARITY_NONE;
  huart7.Init.Mode = UART_MODE_TX_RX;
  huart7.Init.HwFlowCtl = UART_HWCONTROL_NONE;
  huart7.Init.OverSampling = UART_OVERSAMPLING_16;
  huart7.Init.OneBitSampling = UART_ONE_BIT_SAMPLE_DISABLE;
  huart7.Init.ClockPrescaler = UART_PRESCALER_DIV1;
  huart7.AdvancedInit.AdvFeatureInit = UART_ADVFEATURE_NO_INIT;
  if (HAL_UART_Init(&huart7) != HAL_OK)
  {
    Error_Handler();
  }
  if (HAL_UARTEx_SetTxFifoThreshold(&huart7, UART_TXFIFO_THRESHOLD_1_8) != HAL_OK)
  {
    Error_Handler();
  }
  if (HAL_UARTEx_SetRxFifoThreshold(&huart7, UART_RXFIFO_THRESHOLD_1_8) != HAL_OK)
  {
    Error_Handler();
  }
  if (HAL_UARTEx_DisableFifoMode(&huart7) != HAL_OK)
  {
    Error_Handler();
  }

}

static void MX_USART1_UART_Init(void)
{

  huart1.Instance = USART1;
  huart1.Init.BaudRate = 115200;
  huart1.Init.WordLength = UART_WORDLENGTH_8B;
  huart1.Init.StopBits = UART_STOPBITS_1;
  huart1.Init.Parity = UART_PARITY_NONE;
  huart1.Init.Mode = UART_MODE_TX_RX;
  huart1.Init.HwFlowCtl = UART_HWCONTROL_RTS_CTS;
  huart1.Init.OverSampling = UART_OVERSAMPLING_16;
  huart1.Init.OneBitSampling = UART_ONE_BIT_SAMPLE_DISABLE;
  huart1.Init.ClockPrescaler = UART_PRESCALER_DIV1;
  huart1.AdvancedInit.AdvFeatureInit = UART_ADVFEATURE_NO_INIT;
  if (HAL_UART_Init(&huart1) != HAL_OK)
  {
    Error_Handler();
  }
  if (HAL_UARTEx_SetTxFifoThreshold(&huart1, UART_TXFIFO_THRESHOLD_1_8) != HAL_OK)
  {
    Error_Handler();
  }
  if (HAL_UARTEx_SetRxFifoThreshold(&huart1, UART_RXFIFO_THRESHOLD_1_8) != HAL_OK)
  {
    Error_Handler();
  }
  if (HAL_UARTEx_DisableFifoMode(&huart1) != HAL_OK)
  {
    Error_Handler();
  }

}

static void MX_USART2_UART_Init(void)
{

  huart2.Instance = USART2;
  huart2.Init.BaudRate = 115200;
  huart2.Init.WordLength = UART_WORDLENGTH_8B;
  huart2.Init.StopBits = UART_STOPBITS_1;
  huart2.Init.Parity = UART_PARITY_NONE;
  huart2.Init.Mode = UART_MODE_TX_RX;
  huart2.Init.HwFlowCtl = UART_HWCONTROL_NONE;
  huart2.Init.OverSampling = UART_OVERSAMPLING_16;
  huart2.Init.OneBitSampling = UART_ONE_BIT_SAMPLE_DISABLE;
  huart2.Init.ClockPrescaler = UART_PRESCALER_DIV1;
  huart2.AdvancedInit.AdvFeatureInit = UART_ADVFEATURE_NO_INIT;
  if (HAL_UART_Init(&huart2) != HAL_OK)
  {
    Error_Handler();
  }
  if (HAL_UARTEx_SetTxFifoThreshold(&huart2, UART_TXFIFO_THRESHOLD_1_8) != HAL_OK)
  {
    Error_Handler();
  }
  if (HAL_UARTEx_SetRxFifoThreshold(&huart2, UART_RXFIFO_THRESHOLD_1_8) != HAL_OK)
  {
    Error_Handler();
  }
  if (HAL_UARTEx_DisableFifoMode(&huart2) != HAL_OK)
  {
    Error_Handler();
  }

}

static void MX_USART3_UART_Init(void)
{

  huart3.Instance = USART3;
  huart3.Init.BaudRate = 115200;
  huart3.Init.WordLength = UART_WORDLENGTH_8B;
  huart3.Init.StopBits = UART_STOPBITS_1;
  huart3.Init.Parity = UART_PARITY_NONE;
  huart3.Init.Mode = UART_MODE_TX_RX;
  huart3.Init.HwFlowCtl = UART_HWCONTROL_NONE;
  huart3.Init.OverSampling = UART_OVERSAMPLING_16;
  huart3.Init.OneBitSampling = UART_ONE_BIT_SAMPLE_DISABLE;
  huart3.Init.ClockPrescaler = UART_PRESCALER_DIV1;
  huart3.AdvancedInit.AdvFeatureInit = UART_ADVFEATURE_NO_INIT;
  if (HAL_UART_Init(&huart3) != HAL_OK)
  {
    Error_Handler();
  }
  if (HAL_UARTEx_SetTxFifoThreshold(&huart3, UART_TXFIFO_THRESHOLD_1_8) != HAL_OK)
  {
    Error_Handler();
  }
  if (HAL_UARTEx_SetRxFifoThreshold(&huart3, UART_RXFIFO_THRESHOLD_1_8) != HAL_OK)
  {
    Error_Handler();
  }
  if (HAL_UARTEx_DisableFifoMode(&huart3) != HAL_OK)
  {
    Error_Handler();
  }

}

static void MX_DMA_Init(void)
{

  /* DMA controller clock enable */
  __HAL_RCC_DMA1_CLK_ENABLE();

  /* DMA interrupt init */
  /* DMA1_Stream0_IRQn interrupt configuration */
  HAL_NVIC_SetPriority(DMA1_Stream0_IRQn, 5, 0);
  HAL_NVIC_EnableIRQ(DMA1_Stream0_IRQn);

}

static void MX_GPIO_Init(void)
{
  GPIO_InitTypeDef GPIO_InitStruct = {0};

  /* GPIO Ports Clock Enable */
  __HAL_RCC_GPIOE_CLK_ENABLE();
  __HAL_RCC_GPIOC_CLK_ENABLE();
  __HAL_RCC_GPIOH_CLK_ENABLE();
  __HAL_RCC_GPIOA_CLK_ENABLE();
  __HAL_RCC_GPIOB_CLK_ENABLE();
  __HAL_RCC_GPIOD_CLK_ENABLE();

  /*Configure GPIO pin Output Level */
  HAL_GPIO_WritePin(GPIOE, GPIO_PIN_3, GPIO_PIN_RESET);

  /*Configure GPIO pin Output Level */
  HAL_GPIO_WritePin(LCD_CS_GPIO_Port, LCD_CS_Pin, GPIO_PIN_SET);

  /*Configure GPIO pin Output Level */
  HAL_GPIO_WritePin(GPIOD, GPIO_PIN_6, GPIO_PIN_RESET);

  /*Configure GPIO pin : PE3 */
  GPIO_InitStruct.Pin = GPIO_PIN_3;
  GPIO_InitStruct.Mode = GPIO_MODE_OUTPUT_PP;
  GPIO_InitStruct.Pull = GPIO_NOPULL;
  GPIO_InitStruct.Speed = GPIO_SPEED_FREQ_LOW;
  HAL_GPIO_Init(GPIOE, &GPIO_InitStruct);

  /*Configure GPIO pin : K1_Pin */
  GPIO_InitStruct.Pin = K1_Pin;
  GPIO_InitStruct.Mode = GPIO_MODE_INPUT;
  GPIO_InitStruct.Pull = GPIO_PULLDOWN;
  HAL_GPIO_Init(K1_GPIO_Port, &GPIO_InitStruct);

  /*Configure GPIO pins : PC0 PC1 PC3 PC5 */
  GPIO_InitStruct.Pin = GPIO_PIN_0|GPIO_PIN_1|GPIO_PIN_3|GPIO_PIN_5;
  GPIO_InitStruct.Mode = GPIO_MODE_IT_RISING;
  GPIO_InitStruct.Pull = GPIO_NOPULL;
  HAL_GPIO_Init(GPIOC, &GPIO_InitStruct);

  /*Configure GPIO pin : LCD_CS_Pin */
  GPIO_InitStruct.Pin = LCD_CS_Pin;
  GPIO_InitStruct.Mode = GPIO_MODE_OUTPUT_PP;
  GPIO_InitStruct.Pull = GPIO_NOPULL;
  GPIO_InitStruct.Speed = GPIO_SPEED_FREQ_VERY_HIGH;
  HAL_GPIO_Init(LCD_CS_GPIO_Port, &GPIO_InitStruct);

  /*Configure GPIO pin : PE15 */
  GPIO_InitStruct.Pin = GPIO_PIN_15;
  GPIO_InitStruct.Mode = GPIO_MODE_IT_RISING;
  GPIO_InitStruct.Pull = GPIO_NOPULL;
  HAL_GPIO_Init(GPIOE, &GPIO_InitStruct);

  /*Configure GPIO pins : PD10 PD14 PD4 */
  GPIO_InitStruct.Pin = GPIO_PIN_10|GPIO_PIN_14|GPIO_PIN_4;
  GPIO_InitStruct.Mode = GPIO_MODE_IT_RISING;
  GPIO_InitStruct.Pull = GPIO_NOPULL;
  HAL_GPIO_Init(GPIOD, &GPIO_InitStruct);

  /*Configure GPIO pin : PA8 */
  GPIO_InitStruct.Pin = GPIO_PIN_8;
  GPIO_InitStruct.Mode = GPIO_MODE_AF_PP;
  GPIO_InitStruct.Pull = GPIO_NOPULL;
  GPIO_InitStruct.Speed = GPIO_SPEED_FREQ_LOW;
  GPIO_InitStruct.Alternate = GPIO_AF0_MCO;
  HAL_GPIO_Init(GPIOA, &GPIO_InitStruct);

  /*Configure GPIO pin : PD6 */
  GPIO_InitStruct.Pin = GPIO_PIN_6;
  GPIO_InitStruct.Mode = GPIO_MODE_OUTPUT_PP;
  GPIO_InitStruct.Pull = GPIO_NOPULL;
  GPIO_InitStruct.Speed = GPIO_SPEED_FREQ_HIGH;
  HAL_GPIO_Init(GPIOD, &GPIO_InitStruct);

}

void StartDefaultTask(void *argument)
{
  for(;;)
  {
    osDelay(1);
  }
}

 /* MPU Configuration */

void MPU_Config(void)
{
  MPU_Region_InitTypeDef MPU_InitStruct = {0};

  /* Disables the MPU */
  HAL_MPU_Disable();

  /** Initializes and configures the Region and the memory to be protected
  */
  MPU_InitStruct.Enable = MPU_REGION_ENABLE;
  MPU_InitStruct.Number = MPU_REGION_NUMBER0;
  MPU_InitStruct.BaseAddress = 0x0;
  MPU_InitStruct.Size = MPU_REGION_SIZE_4GB;
  MPU_InitStruct.SubRegionDisable = 0x87;
  MPU_InitStruct.TypeExtField = MPU_TEX_LEVEL0;
  MPU_InitStruct.AccessPermission = MPU_REGION_NO_ACCESS;
  MPU_InitStruct.DisableExec = MPU_INSTRUCTION_ACCESS_DISABLE;
  MPU_InitStruct.IsShareable = MPU_ACCESS_SHAREABLE;
  MPU_InitStruct.IsCacheable = MPU_ACCESS_NOT_CACHEABLE;
  MPU_InitStruct.IsBufferable = MPU_ACCESS_NOT_BUFFERABLE;

  HAL_MPU_ConfigRegion(&MPU_InitStruct);
  /* Enables the MPU */
  HAL_MPU_Enable(MPU_PRIVILEGED_DEFAULT);

}

void Error_Handler(void)
{
  __disable_irq();
  while (1)
  {
  }
}

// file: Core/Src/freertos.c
/* USER CODE BEGIN Header */
/**
  ******************************************************************************
  * File Name          : freertos.c
  * Description        : FreeRTOS application tasks for ROS2 flight controller
  ******************************************************************************
  */
/* USER CODE END Header */

#include "FreeRTOS.h"
#include "task.h"
#include "cmsis_os2.h"
#include "main.h"

/* USER CODE BEGIN Includes */
#include "debug_uart.h"
#include "ros2_comm.h"
#include "ros2_sensor.h"
#include "ros2_motor.h"
#include "flight_controller.h"
#include "imu_port.h"
#include "fdcan_comm.h"
#include "sd_logger.h"
#include "ota_update.h"
/* USER CODE END Includes */

/* USER CODE BEGIN PD */

/* Task stack sizes (in words, multiply by 4 for bytes) */
#define TASK_STACK_SENSOR        (256)
#define TASK_STACK_MOTOR         (256)
#define TASK_STACK_FDCAN         (256)
#define TASK_STACK_SDLOG         (512)
#define TASK_STACK_ROS2_COMM     (512)
#define TASK_STACK_FLIGHT        (1024)

/* Task priorities */
#define TASK_PRIO_SENSOR         (osPriorityAboveNormal)
#define TASK_PRIO_MOTOR          (osPriorityHigh)
#define TASK_PRIO_ROS2_COMM      (osPriorityNormal)
#define TASK_PRIO_FDCAN          (osPriorityNormal)
#define TASK_PRIO_SDLOG          (osPriorityBelowNormal)

/* Heartbeat interval */
#define HEARTBEAT_INTERVAL_MS    1000

/* USER CODE END PD */

/* USER CODE BEGIN Variables */

static osThreadId_t ros2CommTaskHandle;
static osThreadId_t sensorTaskHandle;
static osThreadId_t motorTaskHandle;
static osThreadId_t fdcanTaskHandle;
static osThreadId_t sdlogTaskHandle;
static osThreadId_t flightTaskHandle;
static imu_port_t imu0_port;
static imu_port_t imu1_port;

/* USER CODE END Variables */

/* USER CODE BEGIN FunctionPrototypes */
static void ROS2_Comm_Task(void *argument);
static void System_Heartbeat_Task(void *argument);
/* USER CODE END FunctionPrototypes */

/* USER CODE BEGIN Application */

/**
 * @brief ROS2 Communication main task
 *        Processes incoming UART messages and dispatches to modules
 */
static void ROS2_Comm_Task(void *argument)
{
    DEBUG_INFO("[ROS2] Communication task started");

    while (1) {
        ROS2_Comm_Process();
        vTaskDelay(pdMS_TO_TICKS(5));  /* ~200Hz processing rate */
    }
}

/**
 * @brief System heartbeat task
 *        Sends periodic status to ROS2 and checks system health
 */
static void System_Heartbeat_Task(void *argument)
{
    DEBUG_INFO("[Heartbeat] Task started (interval: %dms)", HEARTBEAT_INTERVAL_MS);

    /* Wait a bit before first heartbeat */
    vTaskDelay(pdMS_TO_TICKS(1000));

    while (1) {
        uint32_t now = osKernelGetTickCount();
        uint32_t uptime = now;

        /* Get free heap */
        uint32_t free_heap = (uint32_t)xPortGetFreeHeapSize();

        /* Get active bank from OTA config */
        const ota_context_t *ota = OTA_GetContext();
        uint8_t bank = (ota && ota->initialized) ? ota->config.active_bank : 0;

        /* Send heartbeat to ROS2 */
        ROS2_SendStatus(uptime, free_heap, bank);

        vTaskDelay(pdMS_TO_TICKS(HEARTBEAT_INTERVAL_MS));
    }
}

/* USER CODE END Application */

/* =========================================================================== */
/* CubeMX-generated code below - DO NOT MODIFY                                 */
/* =========================================================================== */

extern osThreadId_t defaultTaskHandle;
extern const osThreadAttr_t defaultTask_attributes;

extern void StartDefaultTask(void *argument);

void MX_FREERTOS_Init(void)
{
    /* USER CODE BEGIN Init */

    /* Initialize modules */
    ROS2_Comm_Init();
    ROS2_Sensor_Init();
    ROS2_Motor_Init();
    IMU_Port_Null_Init(&imu0_port);
    IMU_Port_Null_Init(&imu1_port);
    (void)FC_Init(&imu0_port, &imu1_port);
    FDCAN_Comm_Init();
    OTA_Init();
    SD_Logger_Init();

    /* USER CODE END Init */

    /* Create the thread(s) */
    defaultTaskHandle = osThreadNew(StartDefaultTask, NULL, &defaultTask_attributes);

    /* USER CODE BEGIN RTOS_THREADS */

    /* Create application tasks */
    ros2CommTaskHandle = osThreadNew(
        ROS2_Comm_Task, NULL,
        &(const osThreadAttr_t){
            .name = "ros2Comm",
            .stack_size = TASK_STACK_ROS2_COMM * 4,
            .priority = TASK_PRIO_ROS2_COMM,
        });

    sensorTaskHandle = osThreadNew(
        ROS2_Sensor_Task, NULL,
        &(const osThreadAttr_t){
            .name = "sensor",
            .stack_size = TASK_STACK_SENSOR * 4,
            .priority = TASK_PRIO_SENSOR,
        });

    motorTaskHandle = osThreadNew(
        ROS2_Motor_Task, NULL,
        &(const osThreadAttr_t){
            .name = "motor",
            .stack_size = TASK_STACK_MOTOR * 4,
            .priority = TASK_PRIO_MOTOR,
        });

    flightTaskHandle = osThreadNew(
        FC_Task, NULL,
        &(const osThreadAttr_t){
            .name = "flight",
            .stack_size = TASK_STACK_FLIGHT * 4,
            .priority = TASK_PRIO_MOTOR,
        });

    fdcanTaskHandle = osThreadNew(
        FDCAN_Comm_Task, NULL,
        &(const osThreadAttr_t){
            .name = "fdcan",
            .stack_size = TASK_STACK_FDCAN * 4,
            .priority = TASK_PRIO_FDCAN,
        });

    sdlogTaskHandle = osThreadNew(
        SD_Logger_Task, NULL,
        &(const osThreadAttr_t){
            .name = "sdlog",
            .stack_size = TASK_STACK_SDLOG * 4,
            .priority = TASK_PRIO_SDLOG,
        });

    /* Start heartbeat as a bare FreeRTOS task (uses DEBUG UART) */
    xTaskCreate(System_Heartbeat_Task, "heartbeat", 256 * 4, NULL,
                 osPriorityBelowNormal, NULL);

    DEBUG_INFO("[RTOS] All tasks created");
    DEBUG_INFO("[RTOS] Tasks: ros2Comm, sensor, motor, flight, fdcan, sdlog, heartbeat, default");

    /* USER CODE END RTOS_THREADS */
}
